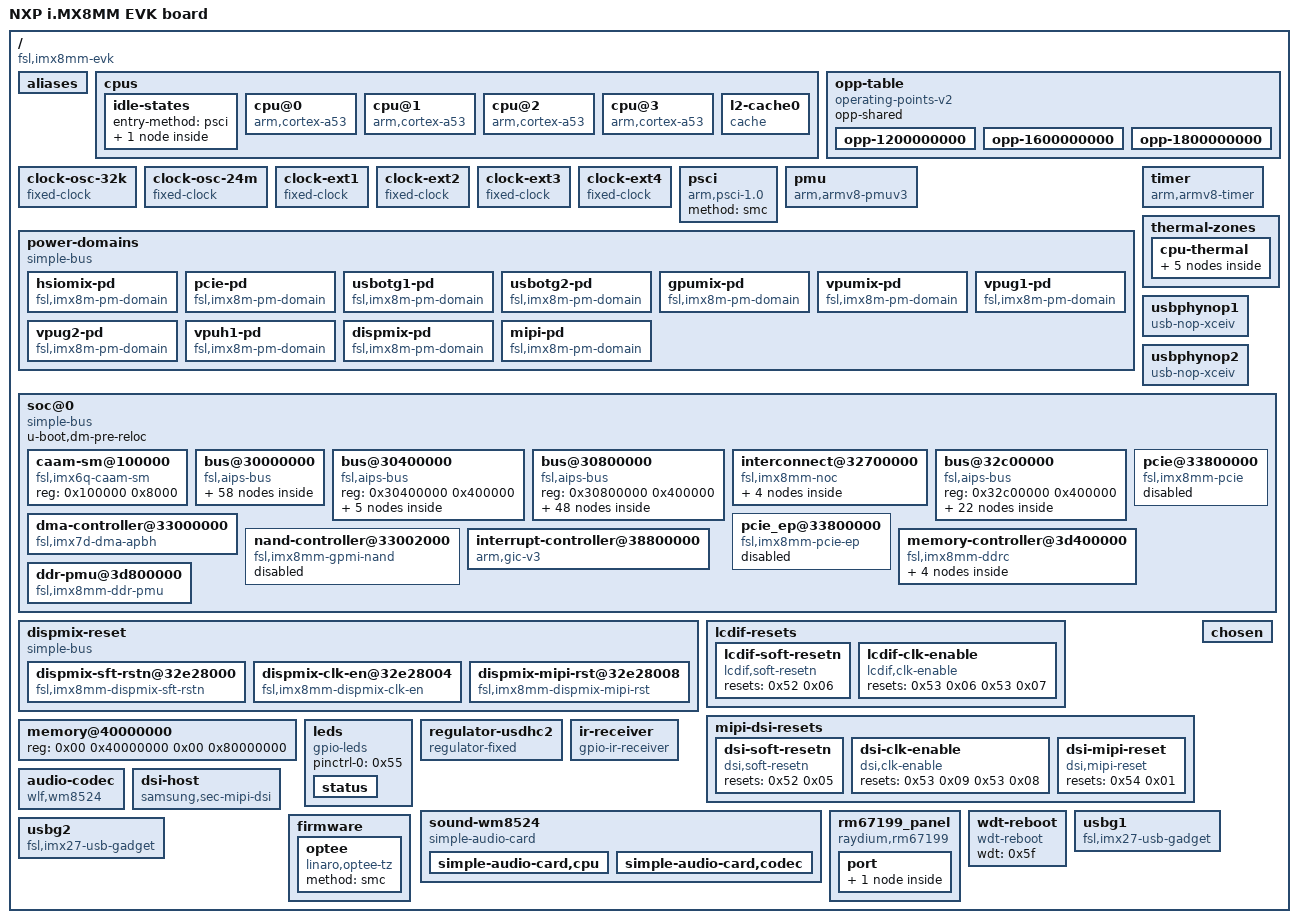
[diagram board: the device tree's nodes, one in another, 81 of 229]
/dts-v1/;

/ {
	interrupt-parent = <0x01>;
	#address-cells = <0x02>;
	#size-cells = <0x02>;
	model = "NXP i.MX8MM EVK board";
	compatible = "fsl,imx8mm-evk\0fsl,imx8mm";

	aliases {
		ethernet0 = "/soc@0/bus@30800000/ethernet@30be0000";
		gpio0 = "/soc@0/bus@30000000/gpio@30200000";
		gpio1 = "/soc@0/bus@30000000/gpio@30210000";
		gpio2 = "/soc@0/bus@30000000/gpio@30220000";
		gpio3 = "/soc@0/bus@30000000/gpio@30230000";
		gpio4 = "/soc@0/bus@30000000/gpio@30240000";
		i2c0 = "/soc@0/bus@30800000/i2c@30a20000";
		i2c1 = "/soc@0/bus@30800000/i2c@30a30000";
		i2c2 = "/soc@0/bus@30800000/i2c@30a40000";
		i2c3 = "/soc@0/bus@30800000/i2c@30a50000";
		mmc0 = "/soc@0/bus@30800000/mmc@30b40000";
		mmc1 = "/soc@0/bus@30800000/mmc@30b50000";
		mmc2 = "/soc@0/bus@30800000/mmc@30b60000";
		serial0 = "/soc@0/bus@30800000/serial@30860000";
		serial1 = "/soc@0/bus@30800000/serial@30890000";
		serial2 = "/soc@0/bus@30800000/serial@30880000";
		serial3 = "/soc@0/bus@30800000/serial@30a60000";
		spi0 = "/soc@0/bus@30800000/spi@30bb0000";
		spi1 = "/soc@0/bus@30800000/spi@30830000";
		spi2 = "/soc@0/bus@30800000/spi@30840000";
		usb0 = "/soc@0/bus@32c00000/usb@32e40000";
		usb1 = "/soc@0/bus@32c00000/usb@32e50000";
		video0 = "/soc@0/bus@32c00000/lcdif@32e00000";
		usbgadget0 = "/usbg1";
		usbgadget1 = "/usbg2";
	};

	cpus {
		#address-cells = <0x01>;
		#size-cells = <0x00>;

		idle-states {
			entry-method = "psci";

			cpu-pd-wait {
				compatible = "arm,idle-state";
				arm,psci-suspend-param = <0x10033>;
				local-timer-stop;
				entry-latency-us = <0x3e8>;
				exit-latency-us = <0x2bc>;
				min-residency-us = <0xa8c>;
				phandle = <0x06>;
			};
		};

		cpu@0 {
			device_type = "cpu";
			compatible = "arm,cortex-a53";
			reg = <0x00>;
			clock-latency = <0xee6c>;
			clocks = <0x02 0xd7>;
			enable-method = "psci";
			next-level-cache = <0x03>;
			operating-points-v2 = <0x04>;
			nvmem-cells = <0x05>;
			nvmem-cell-names = "speed_grade";
			cpu-idle-states = <0x06>;
			#cooling-cells = <0x02>;
			cpu-supply = <0x07>;
			phandle = <0x08>;
		};

		cpu@1 {
			device_type = "cpu";
			compatible = "arm,cortex-a53";
			reg = <0x01>;
			clock-latency = <0xee6c>;
			clocks = <0x02 0xd7>;
			enable-method = "psci";
			next-level-cache = <0x03>;
			operating-points-v2 = <0x04>;
			cpu-idle-states = <0x06>;
			#cooling-cells = <0x02>;
			cpu-supply = <0x07>;
			phandle = <0x09>;
		};

		cpu@2 {
			device_type = "cpu";
			compatible = "arm,cortex-a53";
			reg = <0x02>;
			clock-latency = <0xee6c>;
			clocks = <0x02 0xd7>;
			enable-method = "psci";
			next-level-cache = <0x03>;
			operating-points-v2 = <0x04>;
			cpu-idle-states = <0x06>;
			#cooling-cells = <0x02>;
			cpu-supply = <0x07>;
			phandle = <0x0a>;
		};

		cpu@3 {
			device_type = "cpu";
			compatible = "arm,cortex-a53";
			reg = <0x03>;
			clock-latency = <0xee6c>;
			clocks = <0x02 0xd7>;
			enable-method = "psci";
			next-level-cache = <0x03>;
			operating-points-v2 = <0x04>;
			cpu-idle-states = <0x06>;
			#cooling-cells = <0x02>;
			cpu-supply = <0x07>;
			phandle = <0x0b>;
		};

		l2-cache0 {
			compatible = "cache";
			phandle = <0x03>;
		};
	};

	opp-table {
		compatible = "operating-points-v2";
		opp-shared;
		phandle = <0x04>;

		opp-1200000000 {
			opp-hz = <0x00 0x47868c00>;
			opp-microvolt = <0xcf850>;
			opp-supported-hw = <0x0e 0x07>;
			clock-latency-ns = <0x249f0>;
			opp-suspend;
		};

		opp-1600000000 {
			opp-hz = <0x00 0x5f5e1000>;
			opp-microvolt = <0xe7ef0>;
			opp-supported-hw = <0x0c 0x07>;
			clock-latency-ns = <0x249f0>;
			opp-suspend;
		};

		opp-1800000000 {
			opp-hz = <0x00 0x6b49d200>;
			opp-microvolt = <0xf4240>;
			opp-supported-hw = <0x08 0x03>;
			clock-latency-ns = <0x249f0>;
			opp-suspend;
		};
	};

	clock-osc-32k {
		compatible = "fixed-clock";
		#clock-cells = <0x00>;
		clock-frequency = <0x8000>;
		clock-output-names = "osc_32k";
		phandle = <0x16>;
	};

	clock-osc-24m {
		compatible = "fixed-clock";
		#clock-cells = <0x00>;
		clock-frequency = <0x16e3600>;
		clock-output-names = "osc_24m";
		u-boot,dm-spl;
		u-boot,dm-pre-reloc;
		phandle = <0x17>;
	};

	clock-ext1 {
		compatible = "fixed-clock";
		#clock-cells = <0x00>;
		clock-frequency = <0x7ed6b40>;
		clock-output-names = "clk_ext1";
		phandle = <0x18>;
	};

	clock-ext2 {
		compatible = "fixed-clock";
		#clock-cells = <0x00>;
		clock-frequency = <0x7ed6b40>;
		clock-output-names = "clk_ext2";
		phandle = <0x19>;
	};

	clock-ext3 {
		compatible = "fixed-clock";
		#clock-cells = <0x00>;
		clock-frequency = <0x7ed6b40>;
		clock-output-names = "clk_ext3";
		phandle = <0x1a>;
	};

	clock-ext4 {
		compatible = "fixed-clock";
		#clock-cells = <0x00>;
		clock-frequency = <0x7ed6b40>;
		clock-output-names = "clk_ext4";
		phandle = <0x1b>;
	};

	psci {
		compatible = "arm,psci-1.0";
		method = "smc";
	};

	pmu {
		compatible = "arm,armv8-pmuv3";
		interrupts = <0x01 0x07 0x3f04>;
		interrupt-affinity = <0x08 0x09 0x0a 0x0b>;
	};

	power-domains {
		compatible = "simple-bus";

		hsiomix-pd {
			compatible = "fsl,imx8m-pm-domain";
			#power-domain-cells = <0x00>;
			domain-index = <0x00>;
			domain-name = "hsiomix";
			clocks = <0x02 0xc0>;
			phandle = <0x0c>;
		};

		pcie-pd {
			compatible = "fsl,imx8m-pm-domain";
			#power-domain-cells = <0x00>;
			domain-index = <0x01>;
			domain-name = "pcie";
			parent-domains = <0x0c>;
			clocks = <0x02 0xa9>;
			phandle = <0x4e>;
		};

		usbotg1-pd {
			compatible = "fsl,imx8m-pm-domain";
			#power-domain-cells = <0x00>;
			domain-index = <0x02>;
			domain-name = "usb_otg1";
			parent-domains = <0x0c>;
			phandle = <0x62>;
		};

		usbotg2-pd {
			compatible = "fsl,imx8m-pm-domain";
			#power-domain-cells = <0x00>;
			domain-index = <0x03>;
			domain-name = "usb_otg2";
			parent-domains = <0x0c>;
			phandle = <0x63>;
		};

		gpumix-pd {
			compatible = "fsl,imx8m-pm-domain";
			#power-domain-cells = <0x00>;
			domain-index = <0x04>;
			domain-name = "gpumix";
			clocks = <0x02 0xc8 0x02 0x5a 0x02 0xd9 0x02 0xc1>;
			phandle = <0x64>;
		};

		vpumix-pd {
			compatible = "fsl,imx8m-pm-domain";
			#power-domain-cells = <0x00>;
			domain-index = <0x05>;
			domain-name = "vpumix";
			clocks = <0x02 0xd2>;
			phandle = <0x0d>;
		};

		vpug1-pd {
			compatible = "fsl,imx8m-pm-domain";
			#power-domain-cells = <0x00>;
			domain-index = <0x06>;
			domain-name = "vpu_g1";
			parent-domains = <0x0d>;
			clocks = <0x02 0xc7>;
			phandle = <0x65>;
		};

		vpug2-pd {
			compatible = "fsl,imx8m-pm-domain";
			#power-domain-cells = <0x00>;
			domain-index = <0x07>;
			domain-name = "vpu_g2";
			parent-domains = <0x0d>;
			clocks = <0x02 0xca>;
			phandle = <0x66>;
		};

		vpuh1-pd {
			compatible = "fsl,imx8m-pm-domain";
			#power-domain-cells = <0x00>;
			domain-index = <0x08>;
			domain-name = "vpu_h1";
			parent-domains = <0x0d>;
			clocks = <0x02 0xc9>;
			phandle = <0x67>;
		};

		dispmix-pd {
			compatible = "fsl,imx8m-pm-domain";
			#power-domain-cells = <0x00>;
			domain-index = <0x09>;
			domain-name = "dispmix";
			clocks = <0x02 0xcc 0x02 0xcd 0x02 0xce>;
			phandle = <0x0e>;
		};

		mipi-pd {
			compatible = "fsl,imx8m-pm-domain";
			#power-domain-cells = <0x00>;
			domain-index = <0x0a>;
			domain-name = "mipi";
			parent-domains = <0x0e>;
			phandle = <0x42>;
		};
	};

	timer {
		compatible = "arm,armv8-timer";
		interrupts = <0x01 0x0d 0x3f08 0x01 0x0e 0x3f08 0x01 0x0b 0x3f08 0x01 0x0a 0x3f08>;
		clock-frequency = <0x7a1200>;
		arm,no-tick-in-suspend;
	};

	thermal-zones {

		cpu-thermal {
			polling-delay-passive = <0xfa>;
			polling-delay = <0x7d0>;
			thermal-sensors = <0x0f>;

			trips {

				trip0 {
					temperature = <0x14c08>;
					hysteresis = <0x7d0>;
					type = "passive";
					phandle = <0x10>;
				};

				trip1 {
					temperature = <0x17318>;
					hysteresis = <0x7d0>;
					type = "critical";
					phandle = <0x68>;
				};
			};

			cooling-maps {

				map0 {
					trip = <0x10>;
					cooling-device = <0x08 0xffffffff 0xffffffff 0x09 0xffffffff 0xffffffff 0x0a 0xffffffff 0xffffffff 0x0b 0xffffffff 0xffffffff>;
				};
			};
		};
	};

	usbphynop1 {
		compatible = "usb-nop-xceiv";
		clocks = <0x02 0x84>;
		assigned-clocks = <0x02 0x84>;
		assigned-clock-parents = <0x02 0x32>;
		clock-names = "main_clk";
		phandle = <0x47>;
	};

	usbphynop2 {
		compatible = "usb-nop-xceiv";
		clocks = <0x02 0x84>;
		assigned-clocks = <0x02 0x84>;
		assigned-clock-parents = <0x02 0x32>;
		clock-names = "main_clk";
		phandle = <0x4b>;
	};

	soc@0 {
		compatible = "simple-bus";
		#address-cells = <0x01>;
		#size-cells = <0x01>;
		ranges = <0x00 0x00 0x00 0x3e000000>;
		u-boot,dm-pre-reloc;
		u-boot,dm-spl;

		caam-sm@100000 {
			compatible = "fsl,imx6q-caam-sm";
			reg = <0x100000 0x8000>;
			phandle = <0x69>;
		};

		bus@30000000 {
			compatible = "fsl,aips-bus\0simple-bus";
			reg = <0x30000000 0x400000>;
			#address-cells = <0x01>;
			#size-cells = <0x01>;
			ranges = <0x30000000 0x30000000 0x400000>;
			u-boot,dm-spl;
			u-boot,dm-pre-reloc;
			phandle = <0x6a>;

			sai@30010000 {
				#sound-dai-cells = <0x00>;
				compatible = "fsl,imx8mm-sai\0fsl,imx8mq-sai";
				reg = <0x30010000 0x10000>;
				interrupts = <0x00 0x5f 0x04>;
				clocks = <0x02 0xb1 0x02 0x00 0x02 0xb0 0x02 0x00 0x02 0x00>;
				clock-names = "bus\0mclk0\0mclk1\0mclk2\0mclk3";
				dmas = <0x11 0x00 0x02 0x00 0x11 0x01 0x02 0x00>;
				dma-names = "rx\0tx";
				fsl,dataline = <0x00 0xff 0xff>;
				status = "disabled";
				phandle = <0x6b>;
			};

			sai@30020000 {
				#sound-dai-cells = <0x00>;
				compatible = "fsl,imx8mm-sai\0fsl,imx8mq-sai";
				reg = <0x30020000 0x10000>;
				interrupts = <0x00 0x60 0x04>;
				clocks = <0x02 0xb3 0x02 0x00 0x02 0xb2 0x02 0x00 0x02 0x00>;
				clock-names = "bus\0mclk0\0mclk1\0mclk2\0mclk3";
				dmas = <0x11 0x02 0x02 0x00 0x11 0x03 0x02 0x00>;
				dma-names = "rx\0tx";
				status = "disabled";
				phandle = <0x6c>;
			};

			sai@30030000 {
				#sound-dai-cells = <0x00>;
				compatible = "fsl,imx8mm-sai\0fsl,imx8mq-sai";
				reg = <0x30030000 0x10000>;
				interrupts = <0x00 0x32 0x04>;
				clocks = <0x02 0xb5 0x02 0x00 0x02 0xb4 0x02 0x00 0x02 0x00>;
				clock-names = "bus\0mclk0\0mclk1\0mclk2\0mclk3";
				dmas = <0x11 0x04 0x02 0x00 0x11 0x05 0x02 0x00>;
				dma-names = "rx\0tx";
				status = "okay";
				pinctrl-names = "default";
				pinctrl-0 = <0x12>;
				assigned-clocks = <0x02 0x6e>;
				assigned-clock-parents = <0x02 0x26>;
				assigned-clock-rates = <0x1770000>;
				phandle = <0x5b>;
			};

			sai@30050000 {
				#sound-dai-cells = <0x00>;
				compatible = "fsl,imx8mm-sai\0fsl,imx8mq-sai";
				reg = <0x30050000 0x10000>;
				interrupts = <0x00 0x5a 0x04>;
				clocks = <0x02 0xb9 0x02 0x00 0x02 0xb8 0x02 0x00 0x02 0x00>;
				clock-names = "bus\0mclk0\0mclk1\0mclk2\0mclk3";
				dmas = <0x11 0x08 0x02 0x00 0x11 0x09 0x02 0x00>;
				dma-names = "rx\0tx";
				fsl,dataline = <0x00 0x0f 0x0f>;
				status = "disabled";
				phandle = <0x6d>;
			};

			sai@30060000 {
				#sound-dai-cells = <0x00>;
				compatible = "fsl,imx8mm-sai\0fsl,imx8mq-sai";
				reg = <0x30060000 0x10000>;
				interrupts = <0x00 0x5a 0x04>;
				clocks = <0x02 0xbb 0x02 0x00 0x02 0xba 0x02 0x00 0x02 0x00>;
				clock-names = "bus\0mclk0\0mclk1\0mclk2\0mclk3";
				dmas = <0x11 0x0a 0x02 0x00 0x11 0x0b 0x02 0x00>;
				dma-names = "rx\0tx";
				status = "disabled";
				phandle = <0x6e>;
			};

			micfil@30080000 {
				compatible = "fsl,imx8mm-micfil";
				reg = <0x30080000 0x10000>;
				interrupts = <0x00 0x6d 0x04 0x00 0x6e 0x04 0x00 0x2c 0x04 0x00 0x2d 0x04>;
				clocks = <0x02 0xd8 0x02 0xcb 0x02 0x26 0x02 0x27 0x02 0x06>;
				clock-names = "ipg_clk\0ipg_clk_app\0pll8k\0pll11k\0clkext3";
				dmas = <0x11 0x18 0x19 0x80000000>;
				dma-names = "rx";
				status = "disabled";
				phandle = <0x6f>;
			};

			spdif@30090000 {
				compatible = "fsl,imx8mm-spdif";
				reg = <0x30090000 0x10000>;
				interrupts = <0x00 0x06 0x04>;
				clocks = <0x02 0x5e 0x02 0x02 0x02 0x72 0x02 0x00 0x02 0x00 0x02 0x00 0x02 0x5e 0x02 0x00 0x02 0x00 0x02 0x00>;
				clock-names = "core\0rxtx0\0rxtx1\0rxtx2\0rxtx3\0rxtx4\0rxtx5\0rxtx6\0rxtx7\0spba";
				dmas = <0x11 0x1c 0x12 0x00 0x11 0x1d 0x12 0x00>;
				dma-names = "rx\0tx";
				status = "disabled";
				phandle = <0x70>;
			};

			gpio@30200000 {
				compatible = "fsl,imx8mm-gpio\0fsl,imx35-gpio";
				reg = <0x30200000 0x10000>;
				interrupts = <0x00 0x40 0x04 0x00 0x41 0x04>;
				clocks = <0x02 0xdf>;
				gpio-controller;
				#gpio-cells = <0x02>;
				interrupt-controller;
				#interrupt-cells = <0x02>;
				gpio-ranges = <0x13 0x00 0x0a 0x1e>;
				u-boot,dm-spl;
				phandle = <0x24>;
			};

			gpio@30210000 {
				compatible = "fsl,imx8mm-gpio\0fsl,imx35-gpio";
				reg = <0x30210000 0x10000>;
				interrupts = <0x00 0x42 0x04 0x00 0x43 0x04>;
				clocks = <0x02 0xe0>;
				gpio-controller;
				#gpio-cells = <0x02>;
				interrupt-controller;
				#interrupt-cells = <0x02>;
				gpio-ranges = <0x13 0x00 0x28 0x15>;
				u-boot,dm-spl;
				phandle = <0x29>;
			};

			gpio@30220000 {
				compatible = "fsl,imx8mm-gpio\0fsl,imx35-gpio";
				reg = <0x30220000 0x10000>;
				interrupts = <0x00 0x44 0x04 0x00 0x45 0x04>;
				clocks = <0x02 0xe1>;
				gpio-controller;
				#gpio-cells = <0x02>;
				interrupt-controller;
				#interrupt-cells = <0x02>;
				gpio-ranges = <0x13 0x00 0x3d 0x1a>;
				u-boot,dm-spl;
				phandle = <0x56>;
			};

			gpio@30230000 {
				compatible = "fsl,imx8mm-gpio\0fsl,imx35-gpio";
				reg = <0x30230000 0x10000>;
				interrupts = <0x00 0x46 0x04 0x00 0x47 0x04>;
				clocks = <0x02 0xe2>;
				gpio-controller;
				#gpio-cells = <0x02>;
				interrupt-controller;
				#interrupt-cells = <0x02>;
				gpio-ranges = <0x13 0x00 0x57 0x20>;
				u-boot,dm-spl;
				phandle = <0x3a>;
			};

			gpio@30240000 {
				compatible = "fsl,imx8mm-gpio\0fsl,imx35-gpio";
				reg = <0x30240000 0x10000>;
				interrupts = <0x00 0x48 0x04 0x00 0x49 0x04>;
				clocks = <0x02 0xe3>;
				gpio-controller;
				#gpio-cells = <0x02>;
				interrupt-controller;
				#interrupt-cells = <0x02>;
				gpio-ranges = <0x13 0x00 0x77 0x1e>;
				u-boot,dm-spl;
				phandle = <0x1f>;
			};

			tmu@30260000 {
				compatible = "fsl,imx8mm-tmu";
				reg = <0x30260000 0x10000>;
				clocks = <0x02 0xd1>;
				#thermal-sensor-cells = <0x00>;
				phandle = <0x0f>;
			};

			watchdog@30280000 {
				compatible = "fsl,imx8mm-wdt\0fsl,imx21-wdt";
				reg = <0x30280000 0x10000>;
				interrupts = <0x00 0x4e 0x04>;
				clocks = <0x02 0xc4>;
				status = "okay";
				pinctrl-names = "default";
				pinctrl-0 = <0x14>;
				fsl,ext-reset-output;
				u-boot,dm-spl;
				phandle = <0x5f>;
			};

			watchdog@30290000 {
				compatible = "fsl,imx8mm-wdt\0fsl,imx21-wdt";
				reg = <0x30290000 0x10000>;
				interrupts = <0x00 0x4f 0x04>;
				clocks = <0x02 0xc5>;
				status = "disabled";
				phandle = <0x71>;
			};

			watchdog@302a0000 {
				compatible = "fsl,imx8mm-wdt\0fsl,imx21-wdt";
				reg = <0x302a0000 0x10000>;
				interrupts = <0x00 0x0a 0x04>;
				clocks = <0x02 0xc6>;
				status = "disabled";
				phandle = <0x72>;
			};

			dma-controller@302c0000 {
				compatible = "fsl,imx8mm-sdma\0fsl,imx8mq-sdma";
				reg = <0x302c0000 0x10000>;
				interrupts = <0x00 0x67 0x04>;
				clocks = <0x02 0xd4 0x02 0xd4>;
				clock-names = "ipg\0ahb";
				#dma-cells = <0x03>;
				fsl,sdma-ram-script-name = "imx/sdma/sdma-imx7d.bin";
				phandle = <0x11>;
			};

			dma-controller@302b0000 {
				compatible = "fsl,imx8mm-sdma\0fsl,imx8mq-sdma";
				reg = <0x302b0000 0x10000>;
				interrupts = <0x00 0x22 0x04>;
				clocks = <0x02 0xd5 0x02 0xd5>;
				clock-names = "ipg\0ahb";
				#dma-cells = <0x03>;
				fsl,sdma-ram-script-name = "imx/sdma/sdma-imx7d.bin";
				phandle = <0x73>;
			};

			pinctrl@30330000 {
				compatible = "fsl,imx8mm-iomuxc";
				reg = <0x30330000 0x10000>;
				u-boot,dm-spl;
				phandle = <0x13>;

				ecspi2grp {
					fsl,pins = <0x204 0x46c 0x00 0x00 0x00 0x82 0x208 0x470 0x00 0x00 0x00 0x82 0x20c 0x474 0x00 0x00 0x00 0x82>;
					phandle = <0x1d>;
				};

				ecspi2cs {
					fsl,pins = <0x210 0x478 0x00 0x05 0x00 0x40000>;
					phandle = <0x1e>;
				};

				fec1grp {
					fsl,pins = <0x68 0x2d0 0x00 0x00 0x00 0x03 0x6c 0x2d4 0x4c0 0x00 0x01 0x03 0x70 0x2d8 0x00 0x00 0x00 0x1f 0x74 0x2dc 0x00 0x00 0x00 0x1f 0x78 0x2e0 0x00 0x00 0x00 0x1f 0x7c 0x2e4 0x00 0x00 0x00 0x1f 0x9c 0x304 0x00 0x00 0x00 0x91 0x98 0x300 0x00 0x00 0x00 0x91 0x94 0x2fc 0x00 0x00 0x00 0x91 0x90 0x2f8 0x00 0x00 0x00 0x91 0x84 0x2ec 0x00 0x00 0x00 0x1f 0x8c 0x2f4 0x00 0x00 0x00 0x91 0x88 0x2f0 0x00 0x00 0x00 0x91 0x80 0x2e8 0x00 0x00 0x00 0x1f 0x1b4 0x41c 0x00 0x05 0x00 0x19>;
					phandle = <0x38>;
				};

				gpioledgrp {
					fsl,pins = <0x134 0x39c 0x00 0x05 0x00 0x19>;
					phandle = <0x55>;
				};

				irgrp {
					fsl,pins = <0x5c 0x2c4 0x00 0x00 0x00 0x4f>;
					phandle = <0x58>;
				};

				gpiowlfgrp {
					fsl,pins = <0x230 0x498 0x00 0x05 0x00 0xd6>;
					phandle = <0x59>;
				};

				i2c1grp {
					fsl,pins = <0x214 0x47c 0x00 0x00 0x00 0x400001c3 0x218 0x480 0x00 0x00 0x00 0x400001c3>;
					u-boot,dm-spl;
					phandle = <0x21>;
				};

				i2c2grp {
					fsl,pins = <0x21c 0x484 0x00 0x00 0x00 0x400001c3 0x220 0x488 0x00 0x00 0x00 0x400001c3>;
					phandle = <0x25>;
				};

				i2c3grp {
					fsl,pins = <0x224 0x48c 0x00 0x00 0x00 0x400001c3 0x228 0x490 0x00 0x00 0x00 0x400001c3>;
					phandle = <0x2b>;
				};

				i2c1grp-gpio {
					fsl,pins = <0x214 0x47c 0x00 0x05 0x00 0x1c3 0x218 0x480 0x00 0x05 0x00 0x1c3>;
					phandle = <0x22>;
				};

				i2c2grp-gpio {
					fsl,pins = <0x21c 0x484 0x00 0x05 0x00 0x1c3 0x220 0x488 0x00 0x05 0x00 0x1c3>;
					phandle = <0x26>;
				};

				i2c3grp-gpio {
					fsl,pins = <0x224 0x48c 0x00 0x05 0x00 0x1c3 0x228 0x490 0x00 0x05 0x00 0x1c3>;
					phandle = <0x2c>;
				};

				pmicirqgrp {
					fsl,pins = <0x34 0x29c 0x00 0x00 0x00 0x141>;
					u-boot,dm-spl;
					phandle = <0x23>;
				};

				regusdhc2vmmcgrp {
					fsl,pins = <0xec 0x354 0x00 0x05 0x00 0x41>;
					u-boot,dm-spl;
					phandle = <0x57>;
				};

				sai3grp {
					fsl,pins = <0x1d8 0x440 0x00 0x00 0x00 0xd6 0x1dc 0x444 0x00 0x00 0x00 0xd6 0x1e4 0x44c 0x00 0x00 0x00 0xd6 0x1e0 0x448 0x00 0x00 0x00 0xd6>;
					phandle = <0x12>;
				};

				typec1grp {
					fsl,pins = <0xcc 0x334 0x00 0x05 0x00 0x159>;
					phandle = <0x28>;
				};

				uart2grp {
					fsl,pins = <0x23c 0x4a4 0x4fc 0x00 0x00 0x140 0x240 0x4a8 0x00 0x00 0x00 0x140>;
					u-boot,dm-spl;
					phandle = <0x20>;
				};

				usdhc2grpgpiogrp {
					fsl,pins = <0x64 0x2cc 0x00 0x00 0x00 0x1c4>;
					u-boot,dm-spl;
					phandle = <0x2e>;
				};

				usdhc2grp {
					fsl,pins = <0xd4 0x33c 0x00 0x00 0x00 0x190 0xd8 0x340 0x00 0x00 0x00 0x1d0 0xdc 0x344 0x00 0x00 0x00 0x1d0 0xe0 0x348 0x00 0x00 0x00 0x1d0 0xe4 0x34c 0x00 0x00 0x00 0x1d0 0xe8 0x350 0x00 0x00 0x00 0x1d0 0x38 0x2a0 0x00 0x01 0x00 0x1d0>;
					u-boot,dm-spl;
					phandle = <0x2d>;
				};

				usdhc2-100mhzgrp {
					fsl,pins = <0xd4 0x33c 0x00 0x00 0x00 0x194 0xd8 0x340 0x00 0x00 0x00 0x1d4 0xdc 0x344 0x00 0x00 0x00 0x1d4 0xe0 0x348 0x00 0x00 0x00 0x1d4 0xe4 0x34c 0x00 0x00 0x00 0x1d4 0xe8 0x350 0x00 0x00 0x00 0x1d4 0x38 0x2a0 0x00 0x01 0x00 0x1d0>;
					phandle = <0x2f>;
				};

				usdhc2-200mhzgrp {
					fsl,pins = <0xd4 0x33c 0x00 0x00 0x00 0x196 0xd8 0x340 0x00 0x00 0x00 0x1d6 0xdc 0x344 0x00 0x00 0x00 0x1d6 0xe0 0x348 0x00 0x00 0x00 0x1d6 0xe4 0x34c 0x00 0x00 0x00 0x1d6 0xe8 0x350 0x00 0x00 0x00 0x1d6 0x38 0x2a0 0x00 0x01 0x00 0x1d0>;
					phandle = <0x30>;
				};

				wdoggrp {
					fsl,pins = <0x30 0x298 0x00 0x01 0x00 0xc6>;
					phandle = <0x14>;
				};

				mipi_dsi_en {
					fsl,pins = <0x48 0x2b0 0x00 0x00 0x00 0x19>;
					phandle = <0x5d>;
				};

				flexspigrp {
					fsl,pins = <0xf4 0x35c 0x00 0x01 0x00 0x1c2 0xf8 0x360 0x00 0x01 0x00 0x82 0x10c 0x374 0x00 0x01 0x00 0x82 0x110 0x378 0x00 0x01 0x00 0x82 0x114 0x37c 0x00 0x01 0x00 0x82 0x118 0x380 0x00 0x01 0x00 0x82>;
					phandle = <0x35>;
				};

				usdhc3grp {
					fsl,pins = <0x138 0x3a0 0x00 0x12 0x00 0x190 0x13c 0x3a4 0x00 0x02 0x00 0x1d0 0x11c 0x384 0x00 0x02 0x00 0x1d0 0x120 0x388 0x00 0x02 0x00 0x1d0 0x124 0x38c 0x00 0x02 0x00 0x1d0 0x124 0x38c 0x00 0x02 0x00 0x1d0 0x128 0x390 0x00 0x02 0x00 0x1d0 0x130 0x398 0x00 0x02 0x00 0x1d0 0x100 0x368 0x00 0x02 0x00 0x1d0 0x104 0x36c 0x00 0x02 0x00 0x1d0 0x108 0x370 0x00 0x02 0x00 0x1d0 0xfc 0x364 0x00 0x02 0x00 0x190>;
					u-boot,dm-spl;
					phandle = <0x32>;
				};

				usdhc3-100mhzgrp {
					fsl,pins = <0x138 0x3a0 0x00 0x12 0x00 0x194 0x13c 0x3a4 0x00 0x02 0x00 0x1d4 0x11c 0x384 0x00 0x02 0x00 0x1d4 0x120 0x388 0x00 0x02 0x00 0x1d4 0x124 0x38c 0x00 0x02 0x00 0x1d4 0x128 0x390 0x00 0x02 0x00 0x1d4 0x130 0x398 0x00 0x02 0x00 0x1d4 0x100 0x368 0x00 0x02 0x00 0x1d4 0x104 0x36c 0x00 0x02 0x00 0x1d4 0x108 0x370 0x00 0x02 0x00 0x1d4 0xfc 0x364 0x00 0x02 0x00 0x194>;
					phandle = <0x33>;
				};

				usdhc3-200mhzgrp {
					fsl,pins = <0x138 0x3a0 0x00 0x12 0x00 0x196 0x13c 0x3a4 0x00 0x02 0x00 0x1d6 0x11c 0x384 0x00 0x02 0x00 0x1d6 0x120 0x388 0x00 0x02 0x00 0x1d6 0x124 0x38c 0x00 0x02 0x00 0x1d6 0x128 0x390 0x00 0x02 0x00 0x1d6 0x130 0x398 0x00 0x02 0x00 0x1d6 0x100 0x368 0x00 0x02 0x00 0x1d6 0x104 0x36c 0x00 0x02 0x00 0x1d6 0x108 0x370 0x00 0x02 0x00 0x1d6 0xfc 0x364 0x00 0x02 0x00 0x196>;
					phandle = <0x34>;
				};
			};

			iomuxc-gpr@30340000 {
				compatible = "fsl,imx8mm-iomuxc-gpr\0fsl,imx6q-iomuxc-gpr\0syscon";
				reg = <0x30340000 0x10000>;
				phandle = <0x37>;
			};

			efuse@30350000 {
				compatible = "fsl,imx8mm-ocotp\0syscon";
				reg = <0x30350000 0x10000>;
				clocks = <0x02 0xa8>;
				#address-cells = <0x01>;
				#size-cells = <0x01>;
				phandle = <0x74>;

				speed-grade@10 {
					reg = <0x10 0x04>;
					phandle = <0x05>;
				};

				mac-address@640 {
					reg = <0x90 0x06>;
					phandle = <0x36>;
				};
			};

			anatop@30360000 {
				compatible = "fsl,imx8mm-anatop\0syscon";
				reg = <0x30360000 0x10000>;
				phandle = <0x75>;
			};

			caam_secvio {
				compatible = "fsl,imx6q-caam-secvio";
				interrupts = <0x00 0x14 0x04>;
				jtag-tamper = "disabled";
				watchdog-tamper = "enabled";
				internal-boot-tamper = "enabled";
				external-pin-tamper = "disabled";
				phandle = <0x76>;
			};

			caam-snvs@30370000 {
				compatible = "fsl,imx6q-caam-snvs";
				reg = <0x30370000 0x10000>;
				clocks = <0x02 0xe4>;
				clock-names = "ipg";
				phandle = <0x77>;
			};

			snvs@30370000 {
				compatible = "fsl,sec-v4.0-mon\0syscon\0simple-mfd";
				reg = <0x30370000 0x10000>;
				phandle = <0x15>;

				snvs-rtc-lp {
					compatible = "fsl,sec-v4.0-mon-rtc-lp";
					regmap = <0x15>;
					offset = <0x34>;
					interrupts = <0x00 0x13 0x04 0x00 0x14 0x04>;
					clocks = <0x02 0xe4>;
					clock-names = "snvs-rtc";
					phandle = <0x78>;
				};

				snvs-powerkey {
					compatible = "fsl,sec-v4.0-pwrkey";
					regmap = <0x15>;
					interrupts = <0x00 0x04 0x04>;
					clocks = <0x02 0xe4>;
					clock-names = "snvs-pwrkey";
					linux,keycode = <0x74>;
					wakeup-source;
					status = "okay";
					phandle = <0x79>;
				};
			};

			clock-controller@30380000 {
				compatible = "fsl,imx8mm-ccm";
				reg = <0x30380000 0x10000>;
				#clock-cells = <0x01>;
				clocks = <0x16 0x17 0x18 0x19 0x1a 0x1b>;
				clock-names = "osc_32k\0osc_24m\0clk_ext1\0clk_ext2\0clk_ext3\0clk_ext4";
				u-boot,dm-spl;
				u-boot,dm-pre-reloc;
				phandle = <0x02>;
			};

			reset-controller@30390000 {
				compatible = "fsl,imx8mm-src\0fsl,imx8mq-src\0syscon";
				reg = <0x30390000 0x10000>;
				interrupts = <0x00 0x59 0x04>;
				#reset-cells = <0x01>;
				phandle = <0x4f>;
			};
		};

		bus@30400000 {
			compatible = "fsl,aips-bus\0simple-bus";
			reg = <0x30400000 0x400000>;
			#address-cells = <0x01>;
			#size-cells = <0x01>;
			ranges = <0x30400000 0x30400000 0x400000>;
			u-boot,dm-spl;
			phandle = <0x7a>;

			pwm@30660000 {
				compatible = "fsl,imx8mm-pwm\0fsl,imx27-pwm";
				reg = <0x30660000 0x10000>;
				interrupts = <0x00 0x51 0x04>;
				clocks = <0x02 0xaa 0x02 0xaa>;
				clock-names = "ipg\0per";
				#pwm-cells = <0x02>;
				status = "disabled";
				phandle = <0x7b>;
			};

			pwm@30670000 {
				compatible = "fsl,imx8mm-pwm\0fsl,imx27-pwm";
				reg = <0x30670000 0x10000>;
				interrupts = <0x00 0x52 0x04>;
				clocks = <0x02 0xab 0x02 0xab>;
				clock-names = "ipg\0per";
				#pwm-cells = <0x02>;
				status = "disabled";
				phandle = <0x7c>;
			};

			pwm@30680000 {
				compatible = "fsl,imx8mm-pwm\0fsl,imx27-pwm";
				reg = <0x30680000 0x10000>;
				interrupts = <0x00 0x53 0x04>;
				clocks = <0x02 0xac 0x02 0xac>;
				clock-names = "ipg\0per";
				#pwm-cells = <0x02>;
				status = "disabled";
				phandle = <0x7d>;
			};

			pwm@30690000 {
				compatible = "fsl,imx8mm-pwm\0fsl,imx27-pwm";
				reg = <0x30690000 0x10000>;
				interrupts = <0x00 0x54 0x04>;
				clocks = <0x02 0xad 0x02 0xad>;
				clock-names = "ipg\0per";
				#pwm-cells = <0x02>;
				status = "disabled";
				phandle = <0x7e>;
			};

			timer@306a0000 {
				compatible = "nxp,sysctr-timer";
				reg = <0x306a0000 0x20000>;
				interrupts = <0x00 0x2f 0x04>;
				clocks = <0x17>;
				clock-names = "per";
				phandle = <0x7f>;
			};
		};

		bus@30800000 {
			compatible = "fsl,aips-bus\0simple-bus";
			reg = <0x30800000 0x400000>;
			#address-cells = <0x01>;
			#size-cells = <0x01>;
			ranges = <0x30800000 0x30800000 0x400000 0x8000000 0x8000000 0x10000000>;
			u-boot,dm-spl;
			phandle = <0x80>;

			spi@30820000 {
				compatible = "fsl,imx8mm-ecspi\0fsl,imx51-ecspi";
				#address-cells = <0x01>;
				#size-cells = <0x00>;
				reg = <0x30820000 0x10000>;
				interrupts = <0x00 0x1f 0x04>;
				clocks = <0x02 0x9f 0x02 0x9f>;
				clock-names = "ipg\0per";
				dmas = <0x1c 0x00 0x07 0x01 0x1c 0x01 0x07 0x02>;
				dma-names = "rx\0tx";
				status = "disabled";
				phandle = <0x81>;
			};

			spi@30830000 {
				compatible = "fsl,imx8mm-ecspi\0fsl,imx51-ecspi";
				#address-cells = <0x01>;
				#size-cells = <0x00>;
				reg = <0x30830000 0x10000>;
				interrupts = <0x00 0x20 0x04>;
				clocks = <0x02 0xa0 0x02 0xa0>;
				clock-names = "ipg\0per";
				dmas = <0x1c 0x02 0x07 0x01 0x1c 0x03 0x07 0x02>;
				dma-names = "rx\0tx";
				status = "okay";
				fsl,spi-num-chipselects = <0x01>;
				pinctrl-names = "default";
				pinctrl-0 = <0x1d 0x1e>;
				cs-gpios = <0x1f 0x0d 0x01>;
				phandle = <0x82>;

				spi@0 {
					reg = <0x00>;
					compatible = "rohm,dh2228fv";
					spi-max-frequency = <0x7a120>;
					phandle = <0x83>;
				};
			};

			spi@30840000 {
				compatible = "fsl,imx8mm-ecspi\0fsl,imx51-ecspi";
				#address-cells = <0x01>;
				#size-cells = <0x00>;
				reg = <0x30840000 0x10000>;
				interrupts = <0x00 0x21 0x04>;
				clocks = <0x02 0xa1 0x02 0xa1>;
				clock-names = "ipg\0per";
				dmas = <0x1c 0x04 0x07 0x01 0x1c 0x05 0x07 0x02>;
				dma-names = "rx\0tx";
				status = "disabled";
				phandle = <0x84>;
			};

			serial@30860000 {
				compatible = "fsl,imx8mm-uart\0fsl,imx6q-uart";
				reg = <0x30860000 0x10000>;
				interrupts = <0x00 0x1a 0x04>;
				clocks = <0x02 0xbc 0x02 0xbc>;
				clock-names = "ipg\0per";
				dmas = <0x1c 0x16 0x04 0x00 0x1c 0x17 0x04 0x00>;
				dma-names = "rx\0tx";
				status = "disabled";
				phandle = <0x85>;
			};

			serial@30880000 {
				compatible = "fsl,imx8mm-uart\0fsl,imx6q-uart";
				reg = <0x30880000 0x10000>;
				interrupts = <0x00 0x1c 0x04>;
				clocks = <0x02 0xbe 0x02 0xbe>;
				clock-names = "ipg\0per";
				dmas = <0x1c 0x1a 0x04 0x00 0x1c 0x1b 0x04 0x00>;
				dma-names = "rx\0tx";
				status = "disabled";
				phandle = <0x86>;
			};

			serial@30890000 {
				compatible = "fsl,imx8mm-uart\0fsl,imx6q-uart";
				reg = <0x30890000 0x10000>;
				interrupts = <0x00 0x1b 0x04>;
				clocks = <0x02 0xbd 0x02 0xbd>;
				clock-names = "ipg\0per";
				status = "okay";
				pinctrl-names = "default";
				pinctrl-0 = <0x20>;
				u-boot,dm-spl;
				phandle = <0x87>;
			};

			crypto@30900000 {
				compatible = "fsl,sec-v4.0";
				#address-cells = <0x01>;
				#size-cells = <0x01>;
				reg = <0x30900000 0x40000>;
				ranges = <0x00 0x30900000 0x40000>;
				interrupts = <0x00 0x5b 0x04>;
				clocks = <0x02 0x5d 0x02 0x5f>;
				clock-names = "aclk\0ipg";
				phandle = <0x88>;

				jr@1000 {
					compatible = "fsl,sec-v4.0-job-ring";
					reg = <0x1000 0x1000>;
					interrupts = <0x00 0x69 0x04>;
					status = "disabled";
					phandle = <0x89>;
				};

				jr@2000 {
					compatible = "fsl,sec-v4.0-job-ring";
					reg = <0x2000 0x1000>;
					interrupts = <0x00 0x6a 0x04>;
					phandle = <0x8a>;
				};

				jr@3000 {
					compatible = "fsl,sec-v4.0-job-ring";
					reg = <0x3000 0x1000>;
					interrupts = <0x00 0x72 0x04>;
					phandle = <0x8b>;
				};
			};

			i2c@30a20000 {
				compatible = "fsl,imx8mm-i2c\0fsl,imx21-i2c";
				#address-cells = <0x01>;
				#size-cells = <0x00>;
				reg = <0x30a20000 0x10000>;
				interrupts = <0x00 0x23 0x04>;
				clocks = <0x02 0xa4>;
				status = "okay";
				clock-frequency = <0x61a80>;
				pinctrl-names = "default\0gpio";
				pinctrl-0 = <0x21>;
				pinctrl-1 = <0x22>;
				scl-gpios = <0x1f 0x0e 0x00>;
				sda-gpios = <0x1f 0x0f 0x00>;
				u-boot,dm-spl;
				phandle = <0x8c>;

				pca9450@25 {
					reg = <0x25>;
					compatible = "nxp,pca9450a";
					pinctrl-0 = <0x23>;
					gpio_intr = <0x24 0x03 0x01>;
					u-boot,dm-spl;
					phandle = <0x8d>;

					regulators {
						#address-cells = <0x01>;
						#size-cells = <0x00>;
						pca9450,pmic-buck2-uses-i2c-dvs;
						pca9450,pmic-buck2-dvs-voltage = <0xe7ef0 0xcf850>;
						u-boot,dm-spl;

						regulator@0 {
							reg = <0x00>;
							regulator-compatible = "buck1";
							regulator-min-microvolt = <0x927c0>;
							regulator-max-microvolt = <0x2160ec>;
							regulator-boot-on;
							regulator-always-on;
							regulator-ramp-delay = <0xc35>;
							phandle = <0x8e>;
						};

						regulator@1 {
							reg = <0x01>;
							regulator-compatible = "buck2";
							regulator-min-microvolt = <0x927c0>;
							regulator-max-microvolt = <0x2160ec>;
							regulator-boot-on;
							regulator-always-on;
							regulator-ramp-delay = <0xc35>;
							phandle = <0x07>;
						};

						regulator@2 {
							reg = <0x02>;
							regulator-compatible = "buck3";
							regulator-min-microvolt = <0x927c0>;
							regulator-max-microvolt = <0x2160ec>;
							regulator-boot-on;
							regulator-always-on;
							phandle = <0x8f>;
						};

						regulator@3 {
							reg = <0x03>;
							regulator-compatible = "buck4";
							regulator-min-microvolt = <0x927c0>;
							regulator-max-microvolt = <0x33e140>;
							regulator-boot-on;
							regulator-always-on;
							phandle = <0x90>;
						};

						regulator@4 {
							reg = <0x04>;
							regulator-compatible = "buck5";
							regulator-min-microvolt = <0x927c0>;
							regulator-max-microvolt = <0x33e140>;
							regulator-boot-on;
							regulator-always-on;
							phandle = <0x91>;
						};

						regulator@5 {
							reg = <0x05>;
							regulator-compatible = "buck6";
							regulator-min-microvolt = <0x927c0>;
							regulator-max-microvolt = <0x33e140>;
							regulator-boot-on;
							regulator-always-on;
							phandle = <0x92>;
						};

						regulator@6 {
							reg = <0x06>;
							regulator-compatible = "ldo1";
							regulator-min-microvolt = <0x186a00>;
							regulator-max-microvolt = <0x325aa0>;
							regulator-boot-on;
							regulator-always-on;
							phandle = <0x93>;
						};

						regulator@7 {
							reg = <0x07>;
							regulator-compatible = "ldo2";
							regulator-min-microvolt = "\0\f5";
							regulator-max-microvolt = <0x118c30>;
							regulator-boot-on;
							regulator-always-on;
							phandle = <0x94>;
						};

						regulator@8 {
							reg = <0x08>;
							regulator-compatible = "ldo3";
							regulator-min-microvolt = "\0\f5";
							regulator-max-microvolt = <0x325aa0>;
							regulator-boot-on;
							regulator-always-on;
							phandle = <0x95>;
						};

						regulator@9 {
							reg = <0x09>;
							regulator-compatible = "ldo4";
							regulator-min-microvolt = "\0\f5";
							regulator-max-microvolt = <0x325aa0>;
							regulator-boot-on;
							regulator-always-on;
							phandle = <0x96>;
						};

						regulator@10 {
							reg = <0x0a>;
							regulator-compatible = "ldo5";
							regulator-min-microvolt = <0x1b7740>;
							regulator-max-microvolt = <0x325aa0>;
							phandle = <0x97>;
						};
					};
				};
			};

			i2c@30a30000 {
				compatible = "fsl,imx8mm-i2c\0fsl,imx21-i2c";
				#address-cells = <0x01>;
				#size-cells = <0x00>;
				reg = <0x30a30000 0x10000>;
				interrupts = <0x00 0x24 0x04>;
				clocks = <0x02 0xa5>;
				status = "okay";
				clock-frequency = <0x61a80>;
				pinctrl-names = "default\0gpio";
				pinctrl-0 = <0x25>;
				pinctrl-1 = <0x26>;
				scl-gpios = <0x1f 0x10 0x00>;
				sda-gpios = <0x1f 0x11 0x00>;
				phandle = <0x98>;

				adv7535@3d {
					compatible = "adi,adv7533";
					reg = <0x3d>;
					adi,addr-cec = <0x3c>;
					adi,dsi-lanes = <0x04>;
					status = "okay";
					phandle = <0x99>;

					port {

						endpoint {
							remote-endpoint = <0x27>;
							phandle = <0x44>;
						};
					};
				};

				tcpc@50 {
					compatible = "nxp,ptn5110";
					pinctrl-names = "default";
					pinctrl-0 = <0x28>;
					reg = <0x50>;
					interrupt-parent = <0x29>;
					interrupts = <0x0b 0x08>;
					status = "okay";
					phandle = <0x49>;

					port {

						endpoint {
							remote-endpoint = <0x2a>;
							phandle = <0x4a>;
						};
					};

					connector {
						compatible = "usb-c-connector";
						label = "USB-C";
						power-role = "dual";
						data-role = "dual";
						try-power-role = "sink";
						source-pdos = <0x401912c>;
						sink-pdos = <0x401912c 0x9901912c>;
						op-sink-microwatt = <0xe4e1c0>;
						self-powered;
						phandle = <0x9a>;
					};
				};
			};

			i2c@30a40000 {
				#address-cells = <0x01>;
				#size-cells = <0x00>;
				compatible = "fsl,imx8mm-i2c\0fsl,imx21-i2c";
				reg = <0x30a40000 0x10000>;
				interrupts = <0x00 0x25 0x04>;
				clocks = <0x02 0xa6>;
				status = "okay";
				clock-frequency = <0x186a0>;
				pinctrl-names = "default\0gpio";
				pinctrl-0 = <0x2b>;
				pinctrl-1 = <0x2c>;
				scl-gpios = <0x1f 0x12 0x00>;
				sda-gpios = <0x1f 0x13 0x00>;
				phandle = <0x9b>;

				gpio@20 {
					compatible = "ti,tca6416";
					reg = <0x20>;
					gpio-controller;
					#gpio-cells = <0x02>;
					phandle = <0x9c>;
				};
			};

			i2c@30a50000 {
				compatible = "fsl,imx8mm-i2c\0fsl,imx21-i2c";
				#address-cells = <0x01>;
				#size-cells = <0x00>;
				reg = <0x30a50000 0x10000>;
				interrupts = <0x00 0x26 0x04>;
				clocks = <0x02 0xa7>;
				status = "disabled";
				phandle = <0x9d>;
			};

			serial@30a60000 {
				compatible = "fsl,imx8mm-uart\0fsl,imx6q-uart";
				reg = <0x30a60000 0x10000>;
				interrupts = <0x00 0x1d 0x04>;
				clocks = <0x02 0xbf 0x02 0xbf>;
				clock-names = "ipg\0per";
				dmas = <0x1c 0x1c 0x04 0x00 0x1c 0x1d 0x04 0x00>;
				dma-names = "rx\0tx";
				status = "disabled";
				phandle = <0x9e>;
			};

			mailbox@30aa0000 {
				compatible = "fsl,imx8mm-mu\0fsl,imx6sx-mu";
				reg = <0x30aa0000 0x10000>;
				interrupts = <0x00 0x58 0x04>;
				clocks = <0x02 0xda>;
				clock-names = "mu";
				#mbox-cells = <0x02>;
				phandle = <0x9f>;
			};

			mmc@30b40000 {
				compatible = "fsl,imx8mm-usdhc\0fsl,imx7d-usdhc";
				reg = <0x30b40000 0x10000>;
				interrupts = <0x00 0x16 0x04>;
				clocks = <0x02 0x5f 0x02 0x53 0x02 0xc2>;
				clock-names = "ipg\0ahb\0per";
				fsl,tuning-start-tap = <0x14>;
				fsl,tuning-step = <0x02>;
				bus-width = <0x04>;
				status = "disabled";
				u-boot,dm-spl;
				assigned-clocks = <0x02 0x79>;
				assigned-clock-rates = <0x17d78400>;
				assigned-clock-parents = <0x02 0x37>;
				phandle = <0xa0>;
			};

			mmc@30b50000 {
				compatible = "fsl,imx8mm-usdhc\0fsl,imx7d-usdhc";
				reg = <0x30b50000 0x10000>;
				interrupts = <0x00 0x17 0x04>;
				clocks = <0x02 0x5f 0x02 0x53 0x02 0xc3>;
				clock-names = "ipg\0ahb\0per";
				fsl,tuning-start-tap = <0x14>;
				fsl,tuning-step = <0x02>;
				bus-width = <0x04>;
				status = "okay";
				assigned-clocks = <0x02 0x7a>;
				assigned-clock-rates = <0x17d78400>;
				pinctrl-names = "default\0state_100mhz\0state_200mhz";
				pinctrl-0 = <0x2d 0x2e>;
				pinctrl-1 = <0x2f 0x2e>;
				pinctrl-2 = <0x30 0x2e>;
				cd-gpios = <0x24 0x0f 0x01>;
				vmmc-supply = <0x31>;
				u-boot,dm-spl;
				sd-uhs-sdr104;
				sd-uhs-ddr50;
				assigned-clock-parents = <0x02 0x37>;
				fsl,signal-voltage-switch-extra-delay-ms = <0x08>;
				phandle = <0xa1>;
			};

			mmc@30b60000 {
				compatible = "fsl,imx8mm-usdhc\0fsl,imx7d-usdhc";
				reg = <0x30b60000 0x10000>;
				interrupts = <0x00 0x18 0x04>;
				clocks = <0x02 0x5f 0x02 0x53 0x02 0xd0>;
				clock-names = "ipg\0ahb\0per";
				fsl,tuning-start-tap = <0x14>;
				fsl,tuning-step = <0x02>;
				bus-width = <0x08>;
				status = "okay";
				assigned-clocks = <0x02 0x91>;
				assigned-clock-rates = <0x17d78400>;
				pinctrl-names = "default\0state_100mhz\0state_200mhz";
				pinctrl-0 = <0x32>;
				pinctrl-1 = <0x33>;
				pinctrl-2 = <0x34>;
				non-removable;
				u-boot,dm-spl;
				mmc-hs400-1_8v;
				mmc-hs400-enhanced-strobe;
				assigned-clock-parents = <0x02 0x37>;
				phandle = <0xa2>;
			};

			spi@30bb0000 {
				#address-cells = <0x01>;
				#size-cells = <0x00>;
				compatible = "nxp,imx8mm-fspi";
				reg = <0x30bb0000 0x10000 0x8000000 0x10000000>;
				reg-names = "fspi_base\0fspi_mmap";
				interrupts = <0x00 0x6b 0x04>;
				clocks = <0x02 0xae 0x02 0xae>;
				clock-names = "fspi\0fspi_en";
				status = "okay";
				pinctrl-names = "default";
				pinctrl-0 = <0x35>;
				phandle = <0xa3>;

				flash@0 {
					reg = <0x00>;
					#address-cells = <0x01>;
					#size-cells = <0x01>;
					compatible = "jedec,spi-nor";
					spi-max-frequency = <0x4c4b400>;
					spi-tx-bus-width = <0x04>;
					spi-rx-bus-width = <0x04>;
				};
			};

			dma-controller@30bd0000 {
				compatible = "fsl,imx8mm-sdma\0fsl,imx8mq-sdma";
				reg = <0x30bd0000 0x10000>;
				interrupts = <0x00 0x02 0x04>;
				clocks = <0x02 0xd3 0x02 0x5d>;
				clock-names = "ipg\0ahb";
				#dma-cells = <0x03>;
				fsl,sdma-ram-script-name = "imx/sdma/sdma-imx7d.bin";
				phandle = <0x1c>;
			};

			ethernet@30be0000 {
				compatible = "fsl,imx8mm-fec\0fsl,imx8mq-fec\0fsl,imx6sx-fec";
				reg = <0x30be0000 0x10000>;
				interrupts = <0x00 0x76 0x04 0x00 0x77 0x04 0x00 0x78 0x04 0x00 0x79 0x04>;
				clocks = <0x02 0xa2 0x02 0xa2 0x02 0x75 0x02 0x74 0x02 0x76>;
				clock-names = "ipg\0ahb\0ptp\0enet_clk_ref\0enet_out";
				assigned-clocks = <0x02 0x52 0x02 0x75 0x02 0x74 0x02 0x76>;
				assigned-clock-parents = <0x02 0x36 0x02 0x3a 0x02 0x3b 0x02 0x39>;
				assigned-clock-rates = <0x00 0x5f5e100 0x7735940 0x00>;
				fsl,num-tx-queues = <0x03>;
				fsl,num-rx-queues = <0x03>;
				nvmem-cells = <0x36>;
				nvmem-cell-names = "mac-address";
				nvmem_macaddr_swap;
				fsl,stop-mode = <0x37 0x10 0x03>;
				fsl,wakeup_irq = <0x02>;
				status = "okay";
				pinctrl-names = "default";
				pinctrl-0 = <0x38>;
				phy-mode = "rgmii-id";
				phy-handle = <0x39>;
				fsl,magic-packet;
				phy-reset-gpios = <0x3a 0x16 0x01>;
				phandle = <0xa4>;

				mdio {
					#address-cells = <0x01>;
					#size-cells = <0x00>;

					ethernet-phy@0 {
						compatible = "ethernet-phy-ieee802.3-c22";
						reg = <0x00>;
						reset-gpios = <0x3a 0x16 0x01>;
						reset-assert-us = <0x2710>;
						phandle = <0x39>;

						vddio-regulator {
							regulator-name = "VDDIO";
							regulator-min-microvolt = <0x1b7740>;
							regulator-max-microvolt = <0x1b7740>;
							phandle = <0xa5>;
						};
					};
				};
			};
		};

		interconnect@32700000 {
			compatible = "fsl,imx8mm-noc\0fsl,imx8m-noc";
			reg = <0x32700000 0x100000>;
			clocks = <0x02 0x5b>;
			fsl,ddrc = <0x3b>;
			#interconnect-cells = <0x01>;
			operating-points-v2 = <0x3c>;
			phandle = <0xa6>;

			opp-table {
				compatible = "operating-points-v2";
				phandle = <0x3c>;

				opp-150M {
					opp-hz = <0x00 0x8f0d180>;
				};

				opp-375M {
					opp-hz = <0x00 0x165a0bc0>;
				};

				opp-750M {
					opp-hz = <0x00 0x2cb41780>;
				};
			};
		};

		bus@32c00000 {
			compatible = "fsl,aips-bus\0simple-bus";
			reg = <0x32c00000 0x400000>;
			#address-cells = <0x01>;
			#size-cells = <0x01>;
			ranges = <0x32c00000 0x32c00000 0x400000>;
			phandle = <0xa7>;

			lcdif@32e00000 {
				#address-cells = <0x01>;
				#size-cells = <0x00>;
				compatible = "fsl,imx8mm-lcdif";
				reg = <0x32e00000 0x10000>;
				clocks = <0x02 0x6b 0x02 0xcd 0x02 0xce>;
				clock-names = "pix\0disp-axi\0disp-apb";
				interrupts = <0x00 0x05 0x04>;
				lcdif-gpr = <0x3d>;
				resets = <0x3e>;
				power-domains = <0x0e>;
				status = "okay";
				display = <0x3f>;
				phandle = <0xa8>;

				port@0 {
					reg = <0x00>;
					phandle = <0x46>;

					endpoint {
						remote-endpoint = <0x40>;
						phandle = <0x43>;
					};
				};

				display@0 {
					bits-per-pixel = <0x18>;
					bus-width = <0x18>;
					phandle = <0x3f>;
				};
			};

			mipi_dsi@32e10000 {
				#address-cells = <0x01>;
				#size-cells = <0x00>;
				compatible = "fsl,imx8mm-mipi-dsim";
				reg = <0x32e10000 0x400>;
				clocks = <0x02 0x8e 0x02 0x8f>;
				clock-names = "cfg\0pll-ref";
				interrupts = <0x00 0x12 0x04>;
				dsi-gpr = <0x3d>;
				resets = <0x41>;
				power-domains = <0x42>;
				status = "okay";
				phandle = <0xa9>;

				port@0 {

					endpoint {
						remote-endpoint = <0x43>;
						phandle = <0x40>;
					};
				};

				port@1 {

					endpoint {
						remote-endpoint = <0x44>;
						phandle = <0x27>;
					};
				};

				port@2 {

					endpoint {
						remote-endpoint = <0x45>;
						phandle = <0x5e>;
					};
				};
			};

			csi1_bridge@32e20000 {
				compatible = "fsl,imx8mm-csi\0fsl,imx8mq-csi\0fsl,imx6s-csi";
				reg = <0x32e20000 0x1000>;
				interrupts = <0x00 0x10 0x04>;
				clocks = <0x02 0xcd 0x02 0xdb 0x02 0xce>;
				clock-names = "disp-axi\0csi_mclk\0disp_dcic";
				power-domains = <0x0e>;
				status = "disabled";
				phandle = <0xaa>;
			};

			mipi_csi@32e30000 {
				compatible = "fsl,imx8mm-mipi-csi";
				reg = <0x32e30000 0x1000>;
				interrupts = <0x00 0x11 0x04>;
				clock-frequency = <0x13d92d40>;
				clocks = <0x02 0x92 0x02 0x93 0x02 0xcd 0x02 0xce>;
				clock-names = "mipi_clk\0phy_clk\0disp_axi\0disp_apb";
				bus-width = <0x04>;
				power-domains = <0x42>;
				status = "disabled";
				phandle = <0xab>;
			};

			display-gpr@32e28000 {
				compatible = "fsl, imx8mm-iomuxc-gpr\0syscon";
				reg = <0x32e28000 0x100>;
				phandle = <0x3d>;
			};

			display-subsystem {
				compatible = "fsl,imx-display-subsystem";
				ports = <0x46>;
			};

			usb@32e40000 {
				compatible = "fsl,imx8mm-usb\0fsl,imx7d-usb\0fsl,imx27-usb";
				reg = <0x32e40000 0x200>;
				interrupts = <0x00 0x28 0x04>;
				clocks = <0x02 0xc0>;
				clock-names = "usb1_ctrl_root_clk";
				assigned-clocks = <0x02 0x58 0x02 0x83>;
				assigned-clock-parents = <0x02 0x40 0x02 0x32>;
				fsl,usbphy = <0x47>;
				fsl,usbmisc = <0x48 0x00>;
				status = "okay";
				dr_mode = "otg";
				hnp-disable;
				srp-disable;
				adp-disable;
				usb-role-switch;
				disable-over-current;
				samsung,picophy-pre-emp-curr-control = <0x03>;
				samsung,picophy-dc-vol-level-adjust = <0x07>;
				extcon = <0x49>;
				phandle = <0x60>;

				port {

					endpoint {
						remote-endpoint = <0x4a>;
						phandle = <0x2a>;
					};
				};
			};

			usbmisc@32e40200 {
				compatible = "fsl,imx8mm-usbmisc\0fsl,imx7d-usbmisc";
				#index-cells = <0x01>;
				reg = <0x32e40200 0x200>;
				phandle = <0x48>;
			};

			usb@32e50000 {
				compatible = "fsl,imx8mm-usb\0fsl,imx7d-usb\0fsl,imx27-usb";
				reg = <0x32e50000 0x200>;
				interrupts = <0x00 0x29 0x04>;
				clocks = <0x02 0xc0>;
				clock-names = "usb1_ctrl_root_clk";
				assigned-clocks = <0x02 0x58 0x02 0x83>;
				assigned-clock-parents = <0x02 0x40 0x02 0x32>;
				fsl,usbphy = <0x4b>;
				fsl,usbmisc = <0x4c 0x00>;
				status = "disabled";
				phandle = <0x61>;
			};

			usbmisc@32e50200 {
				compatible = "fsl,imx8mm-usbmisc\0fsl,imx7d-usbmisc";
				#index-cells = <0x01>;
				reg = <0x32e50200 0x200>;
				phandle = <0x4c>;
			};

			pcie-phy@32f00000 {
				compatible = "fsl,imx7d-pcie-phy";
				reg = <0x32f00000 0x10000>;
				phandle = <0x50>;
			};
		};

		dma-controller@33000000 {
			compatible = "fsl,imx7d-dma-apbh\0fsl,imx28-dma-apbh";
			reg = <0x33000000 0x2000>;
			interrupts = <0x00 0x0c 0x04 0x00 0x0c 0x04 0x00 0x0c 0x04 0x00 0x0c 0x04>;
			interrupt-names = "gpmi0\0gpmi1\0gpmi2\0gpmi3";
			#dma-cells = <0x01>;
			dma-channels = <0x04>;
			clocks = <0x02 0xde>;
			phandle = <0x4d>;
		};

		nand-controller@33002000 {
			compatible = "fsl,imx8mm-gpmi-nand\0fsl,imx7d-gpmi-nand";
			#address-cells = <0x01>;
			#size-cells = <0x01>;
			reg = <0x33002000 0x2000 0x33004000 0x4000>;
			reg-names = "gpmi-nand\0bch";
			interrupts = <0x00 0x0e 0x04>;
			interrupt-names = "bch";
			clocks = <0x02 0xaf 0x02 0xde>;
			clock-names = "gpmi_io\0gpmi_bch_apb";
			dmas = <0x4d 0x00>;
			dma-names = "rx-tx";
			status = "disabled";
			phandle = <0xac>;
		};

		pcie@33800000 {
			compatible = "fsl,imx8mm-pcie\0snps,dw-pcie";
			reg = <0x33800000 0x400000 0x1ff00000 0x80000>;
			reg-names = "dbi\0config";
			#address-cells = <0x03>;
			#size-cells = <0x02>;
			device_type = "pci";
			bus-range = <0x00 0xff>;
			ranges = <0x81000000 0x00 0x00 0x1ff80000 0x00 0x10000 0x82000000 0x00 0x18000000 0x18000000 0x00 0x7f00000>;
			num-lanes = <0x01>;
			num-viewport = <0x04>;
			interrupts = <0x00 0x7a 0x04>;
			interrupt-names = "msi";
			#interrupt-cells = <0x01>;
			interrupt-map-mask = <0x00 0x00 0x00 0x07>;
			interrupt-map = <0x00 0x00 0x00 0x01 0x01 0x00 0x7d 0x04 0x00 0x00 0x00 0x02 0x01 0x00 0x7c 0x04 0x00 0x00 0x00 0x03 0x01 0x00 0x7b 0x04 0x00 0x00 0x00 0x04 0x01 0x00 0x7a 0x04>;
			linux,pci-domain = <0x00>;
			fsl,max-link-speed = <0x02>;
			power-domains = <0x4e>;
			resets = <0x4f 0x1a 0x4f 0x1c 0x4f 0x32 0x4f 0x1d>;
			reset-names = "pciephy\0apps\0clkreq\0turnoff";
			fsl,imx7d-pcie-phy = <0x50>;
			status = "disabled";
			phandle = <0xad>;
		};

		pcie_ep@33800000 {
			compatible = "fsl,imx8mm-pcie-ep";
			reg = <0x33800000 0x400000 0x18000000 0x8000000>;
			reg-names = "regs\0addr_space";
			num-lanes = <0x01>;
			interrupts = <0x00 0x7f 0x04>;
			interrupt-names = "dma";
			fsl,max-link-speed = <0x02>;
			power-domains = <0x4e>;
			resets = <0x4f 0x1a 0x4f 0x1c 0x4f 0x32 0x4f 0x1d>;
			reset-names = "pciephy\0apps\0clkreq\0turnoff";
			fsl,imx7d-pcie-phy = <0x50>;
			num-ib-windows = <0x04>;
			num-ob-windows = <0x04>;
			status = "disabled";
			phandle = <0xae>;
		};

		interrupt-controller@38800000 {
			compatible = "arm,gic-v3";
			reg = <0x38800000 0x10000 0x38880000 0xc0000>;
			#interrupt-cells = <0x03>;
			interrupt-controller;
			interrupts = <0x01 0x09 0x04>;
			phandle = <0x01>;
		};

		memory-controller@3d400000 {
			compatible = "fsl,imx8mm-ddrc\0fsl,imx8m-ddrc";
			reg = <0x3d400000 0x400000>;
			clock-names = "core\0pll\0alt\0apb";
			clocks = <0x02 0xdc 0x02 0x15 0x02 0x61 0x02 0x62>;
			operating-points-v2 = <0x51>;
			phandle = <0x3b>;

			opp-table {
				compatible = "operating-points-v2";
				phandle = <0x51>;

				opp-25M {
					opp-hz = <0x00 0x17d7840>;
				};

				opp-100M {
					opp-hz = <0x00 0x5f5e100>;
				};

				opp-750M {
					opp-hz = <0x00 0x2cb41780>;
				};
			};
		};

		ddr-pmu@3d800000 {
			compatible = "fsl,imx8mm-ddr-pmu\0fsl,imx8m-ddr-pmu";
			reg = <0x3d800000 0x400000>;
			interrupts = <0x00 0x62 0x04>;
		};
	};

	dispmix-reset {
		compatible = "simple-bus";
		#address-cells = <0x02>;
		#size-cells = <0x02>;
		ranges;

		dispmix-sft-rstn@32e28000 {
			compatible = "fsl,imx8mm-dispmix-sft-rstn";
			reg = <0x00 0x32e28000 0x00 0x04>;
			clocks = <0x02 0xce>;
			clock-names = "disp_apb_root_clk";
			active_low;
			power-domains = <0x0e>;
			#reset-cells = <0x01>;
			phandle = <0x52>;
		};

		dispmix-clk-en@32e28004 {
			compatible = "fsl,imx8mm-dispmix-clk-en";
			reg = <0x00 0x32e28004 0x00 0x04>;
			clocks = <0x02 0xce>;
			clock-names = "disp_apb_root_clk";
			power-domains = <0x0e>;
			#reset-cells = <0x01>;
			phandle = <0x53>;
		};

		dispmix-mipi-rst@32e28008 {
			compatible = "fsl,imx8mm-dispmix-mipi-rst";
			reg = <0x00 0x32e28008 0x00 0x04>;
			clocks = <0x02 0xce>;
			clock-names = "disp_apb_root_clk";
			active_low;
			power-domains = <0x0e>;
			#reset-cells = <0x01>;
			phandle = <0x54>;
		};
	};

	lcdif-resets {
		#address-cells = <0x01>;
		#size-cells = <0x00>;
		#reset-cells = <0x00>;
		phandle = <0x3e>;

		lcdif-soft-resetn {
			compatible = "lcdif,soft-resetn";
			resets = <0x52 0x06>;
		};

		lcdif-clk-enable {
			compatible = "lcdif,clk-enable";
			resets = <0x53 0x06 0x53 0x07>;
		};
	};

	mipi-dsi-resets {
		#address-cells = <0x01>;
		#size-cells = <0x00>;
		#reset-cells = <0x00>;
		phandle = <0x41>;

		dsi-soft-resetn {
			compatible = "dsi,soft-resetn";
			resets = <0x52 0x05>;
		};

		dsi-clk-enable {
			compatible = "dsi,clk-enable";
			resets = <0x53 0x09 0x53 0x08>;
		};

		dsi-mipi-reset {
			compatible = "dsi,mipi-reset";
			resets = <0x54 0x01>;
		};
	};

	chosen {
		stdout-path = "/soc@0/bus@30800000/serial@30890000";
		bootargs = "console=ttymxc1,115200 earlycon=ec_imx6q,0x30890000,115200";
	};

	memory@40000000 {
		device_type = "memory";
		reg = <0x00 0x40000000 0x00 0x80000000>;
	};

	leds {
		compatible = "gpio-leds";
		pinctrl-names = "default";
		pinctrl-0 = <0x55>;

		status {
			label = "status";
			gpios = <0x56 0x10 0x00>;
			default-state = "on";
		};
	};

	regulator-usdhc2 {
		compatible = "regulator-fixed";
		pinctrl-names = "default";
		pinctrl-0 = <0x57>;
		regulator-name = "VSD_3V3";
		regulator-min-microvolt = <0x325aa0>;
		regulator-max-microvolt = <0x325aa0>;
		gpio = <0x29 0x13 0x00>;
		enable-active-high;
		u-boot,off-on-delay-us = <0x4e20>;
		u-boot,dm-spl;
		phandle = <0x31>;
	};

	ir-receiver {
		compatible = "gpio-ir-receiver";
		gpios = <0x24 0x0d 0x01>;
		pinctrl-names = "default";
		pinctrl-0 = <0x58>;
		linux,autosuspend-period = <0x7d>;
	};

	audio-codec {
		#sound-dai-cells = <0x00>;
		compatible = "wlf,wm8524";
		pinctrl-names = "default";
		pinctrl-0 = <0x59>;
		wlf,mute-gpios = <0x1f 0x15 0x01>;
		phandle = <0x5c>;
	};

	sound-wm8524 {
		compatible = "simple-audio-card";
		simple-audio-card,name = "wm8524-audio";
		simple-audio-card,format = "i2s";
		simple-audio-card,frame-master = <0x5a>;
		simple-audio-card,bitclock-master = <0x5a>;
		simple-audio-card,widgets = "Line\0Left Line Out Jack\0Line\0Right Line Out Jack";
		simple-audio-card,routing = "Left Line Out Jack\0LINEVOUTL\0Right Line Out Jack\0LINEVOUTR";

		simple-audio-card,cpu {
			sound-dai = <0x5b>;
			dai-tdm-slot-num = <0x02>;
			dai-tdm-slot-width = <0x20>;
			phandle = <0x5a>;
		};

		simple-audio-card,codec {
			sound-dai = <0x5c>;
			clocks = <0x02 0xb4>;
		};
	};

	dsi-host {
		compatible = "samsung,sec-mipi-dsi";
		status = "okay";
		phandle = <0xaf>;
	};

	rm67199_panel {
		compatible = "raydium,rm67199";
		pinctrl-names = "default";
		pinctrl-0 = <0x5d>;
		reset-gpio = <0x24 0x08 0x01>;
		dsi-lanes = <0x04>;
		video-mode = <0x02>;
		panel-width-mm = <0x44>;
		panel-height-mm = <0x79>;
		status = "okay";

		port {

			endpoint {
				remote-endpoint = <0x5e>;
				phandle = <0x45>;
			};
		};
	};

	wdt-reboot {
		compatible = "wdt-reboot";
		wdt = <0x5f>;
		u-boot,dm-spl;
	};

	usbg1 {
		compatible = "fsl,imx27-usb-gadget";
		dr_mode = "peripheral";
		chipidea,usb = <0x60>;
		status = "okay";
		phandle = <0xb0>;
	};

	usbg2 {
		compatible = "fsl,imx27-usb-gadget";
		dr_mode = "peripheral";
		chipidea,usb = <0x61>;
		status = "okay";
		phandle = <0xb1>;
	};

	firmware {

		optee {
			compatible = "linaro,optee-tz";
			method = "smc";
		};
	};

	__symbols__ {
		cpu_pd_wait = "/cpus/idle-states/cpu-pd-wait";
		A53_0 = "/cpus/cpu@0";
		A53_1 = "/cpus/cpu@1";
		A53_2 = "/cpus/cpu@2";
		A53_3 = "/cpus/cpu@3";
		A53_L2 = "/cpus/l2-cache0";
		a53_opp_table = "/opp-table";
		osc_32k = "/clock-osc-32k";
		osc_24m = "/clock-osc-24m";
		clk_ext1 = "/clock-ext1";
		clk_ext2 = "/clock-ext2";
		clk_ext3 = "/clock-ext3";
		clk_ext4 = "/clock-ext4";
		hsiomix_pd = "/power-domains/hsiomix-pd";
		pcie_pd = "/power-domains/pcie-pd";
		usb_otg1_pd = "/power-domains/usbotg1-pd";
		usb_otg2_pd = "/power-domains/usbotg2-pd";
		gpumix_pd = "/power-domains/gpumix-pd";
		vpumix_pd = "/power-domains/vpumix-pd";
		vpu_g1_pd = "/power-domains/vpug1-pd";
		vpu_g2_pd = "/power-domains/vpug2-pd";
		vpu_h1_pd = "/power-domains/vpuh1-pd";
		dispmix_pd = "/power-domains/dispmix-pd";
		mipi_pd = "/power-domains/mipi-pd";
		cpu_alert0 = "/thermal-zones/cpu-thermal/trips/trip0";
		cpu_crit0 = "/thermal-zones/cpu-thermal/trips/trip1";
		usbphynop1 = "/usbphynop1";
		usbphynop2 = "/usbphynop2";
		caam_sm = "/soc@0/caam-sm@100000";
		aips1 = "/soc@0/bus@30000000";
		sai1 = "/soc@0/bus@30000000/sai@30010000";
		sai2 = "/soc@0/bus@30000000/sai@30020000";
		sai3 = "/soc@0/bus@30000000/sai@30030000";
		sai5 = "/soc@0/bus@30000000/sai@30050000";
		sai6 = "/soc@0/bus@30000000/sai@30060000";
		micfil = "/soc@0/bus@30000000/micfil@30080000";
		spdif1 = "/soc@0/bus@30000000/spdif@30090000";
		gpio1 = "/soc@0/bus@30000000/gpio@30200000";
		gpio2 = "/soc@0/bus@30000000/gpio@30210000";
		gpio3 = "/soc@0/bus@30000000/gpio@30220000";
		gpio4 = "/soc@0/bus@30000000/gpio@30230000";
		gpio5 = "/soc@0/bus@30000000/gpio@30240000";
		tmu = "/soc@0/bus@30000000/tmu@30260000";
		wdog1 = "/soc@0/bus@30000000/watchdog@30280000";
		wdog2 = "/soc@0/bus@30000000/watchdog@30290000";
		wdog3 = "/soc@0/bus@30000000/watchdog@302a0000";
		sdma2 = "/soc@0/bus@30000000/dma-controller@302c0000";
		sdma3 = "/soc@0/bus@30000000/dma-controller@302b0000";
		iomuxc = "/soc@0/bus@30000000/pinctrl@30330000";
		pinctrl_ecspi2 = "/soc@0/bus@30000000/pinctrl@30330000/ecspi2grp";
		pinctrl_ecspi2_cs = "/soc@0/bus@30000000/pinctrl@30330000/ecspi2cs";
		pinctrl_fec1 = "/soc@0/bus@30000000/pinctrl@30330000/fec1grp";
		pinctrl_gpio_led = "/soc@0/bus@30000000/pinctrl@30330000/gpioledgrp";
		pinctrl_ir = "/soc@0/bus@30000000/pinctrl@30330000/irgrp";
		pinctrl_gpio_wlf = "/soc@0/bus@30000000/pinctrl@30330000/gpiowlfgrp";
		pinctrl_i2c1 = "/soc@0/bus@30000000/pinctrl@30330000/i2c1grp";
		pinctrl_i2c2 = "/soc@0/bus@30000000/pinctrl@30330000/i2c2grp";
		pinctrl_i2c3 = "/soc@0/bus@30000000/pinctrl@30330000/i2c3grp";
		pinctrl_i2c1_gpio = "/soc@0/bus@30000000/pinctrl@30330000/i2c1grp-gpio";
		pinctrl_i2c2_gpio = "/soc@0/bus@30000000/pinctrl@30330000/i2c2grp-gpio";
		pinctrl_i2c3_gpio = "/soc@0/bus@30000000/pinctrl@30330000/i2c3grp-gpio";
		pinctrl_pmic = "/soc@0/bus@30000000/pinctrl@30330000/pmicirqgrp";
		pinctrl_reg_usdhc2_vmmc = "/soc@0/bus@30000000/pinctrl@30330000/regusdhc2vmmcgrp";
		pinctrl_sai3 = "/soc@0/bus@30000000/pinctrl@30330000/sai3grp";
		pinctrl_typec1 = "/soc@0/bus@30000000/pinctrl@30330000/typec1grp";
		pinctrl_uart2 = "/soc@0/bus@30000000/pinctrl@30330000/uart2grp";
		pinctrl_usdhc2_gpio = "/soc@0/bus@30000000/pinctrl@30330000/usdhc2grpgpiogrp";
		pinctrl_usdhc2 = "/soc@0/bus@30000000/pinctrl@30330000/usdhc2grp";
		pinctrl_usdhc2_100mhz = "/soc@0/bus@30000000/pinctrl@30330000/usdhc2-100mhzgrp";
		pinctrl_usdhc2_200mhz = "/soc@0/bus@30000000/pinctrl@30330000/usdhc2-200mhzgrp";
		pinctrl_wdog = "/soc@0/bus@30000000/pinctrl@30330000/wdoggrp";
		pinctrl_mipi_dsi_en = "/soc@0/bus@30000000/pinctrl@30330000/mipi_dsi_en";
		pinctrl_flexspi = "/soc@0/bus@30000000/pinctrl@30330000/flexspigrp";
		pinctrl_usdhc3 = "/soc@0/bus@30000000/pinctrl@30330000/usdhc3grp";
		pinctrl_usdhc3_100mhz = "/soc@0/bus@30000000/pinctrl@30330000/usdhc3-100mhzgrp";
		pinctrl_usdhc3_200mhz = "/soc@0/bus@30000000/pinctrl@30330000/usdhc3-200mhzgrp";
		gpr = "/soc@0/bus@30000000/iomuxc-gpr@30340000";
		ocotp = "/soc@0/bus@30000000/efuse@30350000";
		cpu_speed_grade = "/soc@0/bus@30000000/efuse@30350000/speed-grade@10";
		fec_mac_address = "/soc@0/bus@30000000/efuse@30350000/mac-address@640";
		anatop = "/soc@0/bus@30000000/anatop@30360000";
		irq_sec_vio = "/soc@0/bus@30000000/caam_secvio";
		caam_snvs = "/soc@0/bus@30000000/caam-snvs@30370000";
		snvs = "/soc@0/bus@30000000/snvs@30370000";
		snvs_rtc = "/soc@0/bus@30000000/snvs@30370000/snvs-rtc-lp";
		snvs_pwrkey = "/soc@0/bus@30000000/snvs@30370000/snvs-powerkey";
		clk = "/soc@0/bus@30000000/clock-controller@30380000";
		src = "/soc@0/bus@30000000/reset-controller@30390000";
		aips2 = "/soc@0/bus@30400000";
		pwm1 = "/soc@0/bus@30400000/pwm@30660000";
		pwm2 = "/soc@0/bus@30400000/pwm@30670000";
		pwm3 = "/soc@0/bus@30400000/pwm@30680000";
		pwm4 = "/soc@0/bus@30400000/pwm@30690000";
		system_counter = "/soc@0/bus@30400000/timer@306a0000";
		aips3 = "/soc@0/bus@30800000";
		ecspi1 = "/soc@0/bus@30800000/spi@30820000";
		ecspi2 = "/soc@0/bus@30800000/spi@30830000";
		spidev0 = "/soc@0/bus@30800000/spi@30830000/spi@0";
		ecspi3 = "/soc@0/bus@30800000/spi@30840000";
		uart1 = "/soc@0/bus@30800000/serial@30860000";
		uart3 = "/soc@0/bus@30800000/serial@30880000";
		uart2 = "/soc@0/bus@30800000/serial@30890000";
		crypto = "/soc@0/bus@30800000/crypto@30900000";
		sec_jr0 = "/soc@0/bus@30800000/crypto@30900000/jr@1000";
		sec_jr1 = "/soc@0/bus@30800000/crypto@30900000/jr@2000";
		sec_jr2 = "/soc@0/bus@30800000/crypto@30900000/jr@3000";
		i2c1 = "/soc@0/bus@30800000/i2c@30a20000";
		pmic = "/soc@0/bus@30800000/i2c@30a20000/pca9450@25";
		buck1_reg = "/soc@0/bus@30800000/i2c@30a20000/pca9450@25/regulators/regulator@0";
		buck2_reg = "/soc@0/bus@30800000/i2c@30a20000/pca9450@25/regulators/regulator@1";
		buck3_reg = "/soc@0/bus@30800000/i2c@30a20000/pca9450@25/regulators/regulator@2";
		buck4_reg = "/soc@0/bus@30800000/i2c@30a20000/pca9450@25/regulators/regulator@3";
		buck5_reg = "/soc@0/bus@30800000/i2c@30a20000/pca9450@25/regulators/regulator@4";
		buck6_reg = "/soc@0/bus@30800000/i2c@30a20000/pca9450@25/regulators/regulator@5";
		ldo1_reg = "/soc@0/bus@30800000/i2c@30a20000/pca9450@25/regulators/regulator@6";
		ldo2_reg = "/soc@0/bus@30800000/i2c@30a20000/pca9450@25/regulators/regulator@7";
		ldo3_reg = "/soc@0/bus@30800000/i2c@30a20000/pca9450@25/regulators/regulator@8";
		ldo4_reg = "/soc@0/bus@30800000/i2c@30a20000/pca9450@25/regulators/regulator@9";
		ldo5_reg = "/soc@0/bus@30800000/i2c@30a20000/pca9450@25/regulators/regulator@10";
		i2c2 = "/soc@0/bus@30800000/i2c@30a30000";
		adv_bridge = "/soc@0/bus@30800000/i2c@30a30000/adv7535@3d";
		adv7535_from_dsim = "/soc@0/bus@30800000/i2c@30a30000/adv7535@3d/port/endpoint";
		ptn5110 = "/soc@0/bus@30800000/i2c@30a30000/tcpc@50";
		typec1_dr_sw = "/soc@0/bus@30800000/i2c@30a30000/tcpc@50/port/endpoint";
		typec1_con = "/soc@0/bus@30800000/i2c@30a30000/tcpc@50/connector";
		i2c3 = "/soc@0/bus@30800000/i2c@30a40000";
		pca6416 = "/soc@0/bus@30800000/i2c@30a40000/gpio@20";
		i2c4 = "/soc@0/bus@30800000/i2c@30a50000";
		uart4 = "/soc@0/bus@30800000/serial@30a60000";
		mu = "/soc@0/bus@30800000/mailbox@30aa0000";
		usdhc1 = "/soc@0/bus@30800000/mmc@30b40000";
		usdhc2 = "/soc@0/bus@30800000/mmc@30b50000";
		usdhc3 = "/soc@0/bus@30800000/mmc@30b60000";
		flexspi = "/soc@0/bus@30800000/spi@30bb0000";
		sdma1 = "/soc@0/bus@30800000/dma-controller@30bd0000";
		fec1 = "/soc@0/bus@30800000/ethernet@30be0000";
		ethphy0 = "/soc@0/bus@30800000/ethernet@30be0000/mdio/ethernet-phy@0";
		vddio0 = "/soc@0/bus@30800000/ethernet@30be0000/mdio/ethernet-phy@0/vddio-regulator";
		noc = "/soc@0/interconnect@32700000";
		noc_opp_table = "/soc@0/interconnect@32700000/opp-table";
		aips4 = "/soc@0/bus@32c00000";
		lcdif = "/soc@0/bus@32c00000/lcdif@32e00000";
		lcdif_disp0 = "/soc@0/bus@32c00000/lcdif@32e00000/port@0";
		lcdif_to_dsim = "/soc@0/bus@32c00000/lcdif@32e00000/port@0/endpoint";
		display0 = "/soc@0/bus@32c00000/lcdif@32e00000/display@0";
		mipi_dsi = "/soc@0/bus@32c00000/mipi_dsi@32e10000";
		dsim_from_lcdif = "/soc@0/bus@32c00000/mipi_dsi@32e10000/port@0/endpoint";
		dsim_to_adv7535 = "/soc@0/bus@32c00000/mipi_dsi@32e10000/port@1/endpoint";
		dsim_to_rm67191 = "/soc@0/bus@32c00000/mipi_dsi@32e10000/port@2/endpoint";
		csi1_bridge = "/soc@0/bus@32c00000/csi1_bridge@32e20000";
		mipi_csi_1 = "/soc@0/bus@32c00000/mipi_csi@32e30000";
		dispmix_gpr = "/soc@0/bus@32c00000/display-gpr@32e28000";
		usbotg1 = "/soc@0/bus@32c00000/usb@32e40000";
		usb1_drd_sw = "/soc@0/bus@32c00000/usb@32e40000/port/endpoint";
		usbmisc1 = "/soc@0/bus@32c00000/usbmisc@32e40200";
		usbotg2 = "/soc@0/bus@32c00000/usb@32e50000";
		usbmisc2 = "/soc@0/bus@32c00000/usbmisc@32e50200";
		pcie_phy = "/soc@0/bus@32c00000/pcie-phy@32f00000";
		dma_apbh = "/soc@0/dma-controller@33000000";
		gpmi = "/soc@0/nand-controller@33002000";
		pcie0 = "/soc@0/pcie@33800000";
		pcie0_ep = "/soc@0/pcie_ep@33800000";
		gic = "/soc@0/interrupt-controller@38800000";
		ddrc = "/soc@0/memory-controller@3d400000";
		ddrc_opp_table = "/soc@0/memory-controller@3d400000/opp-table";
		dispmix_sft_rstn = "/dispmix-reset/dispmix-sft-rstn@32e28000";
		dispmix_clk_en = "/dispmix-reset/dispmix-clk-en@32e28004";
		dispmix_mipi_rst = "/dispmix-reset/dispmix-mipi-rst@32e28008";
		lcdif_resets = "/lcdif-resets";
		mipi_dsi_resets = "/mipi-dsi-resets";
		reg_usdhc2_vmmc = "/regulator-usdhc2";
		wm8524 = "/audio-codec";
		cpudai = "/sound-wm8524/simple-audio-card,cpu";
		dsi_host = "/dsi-host";
		rm67191_from_dsim = "/rm67199_panel/port/endpoint";
		usbg1 = "/usbg1";
		usbg2 = "/usbg2";
	};
};
